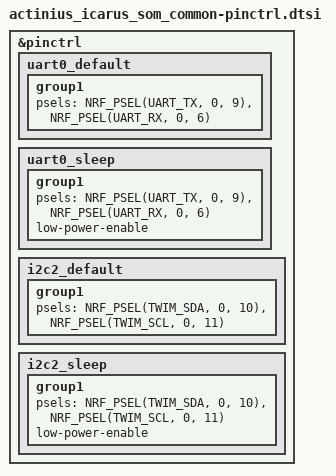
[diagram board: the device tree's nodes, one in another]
/*
 * Copyright (c) 2022 Nordic Semiconductor
 * SPDX-License-Identifier: Apache-2.0
 */

&pinctrl {
	uart0_default: uart0_default {
		group1 {
			psels = <NRF_PSEL(UART_TX, 0, 9)>,
				<NRF_PSEL(UART_RX, 0, 6)>;
		};
	};

	uart0_sleep: uart0_sleep {
		group1 {
			psels = <NRF_PSEL(UART_TX, 0, 9)>,
				<NRF_PSEL(UART_RX, 0, 6)>;
			low-power-enable;
		};
	};

	i2c2_default: i2c2_default {
		group1 {
			psels = <NRF_PSEL(TWIM_SDA, 0, 10)>,
				<NRF_PSEL(TWIM_SCL, 0, 11)>;
		};
	};

	i2c2_sleep: i2c2_sleep {
		group1 {
			psels = <NRF_PSEL(TWIM_SDA, 0, 10)>,
				<NRF_PSEL(TWIM_SCL, 0, 11)>;
			low-power-enable;
		};
	};
};
